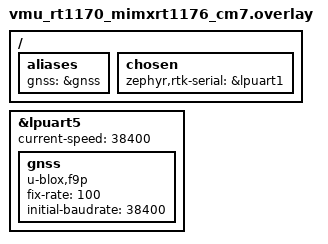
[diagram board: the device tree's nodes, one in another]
/*
 * Copyright 2024, 2026 NXP
 *
 * SPDX-License-Identifier: Apache-2.0
 */

/ {
	aliases {
		gnss = &gnss;
	};

	chosen {
		zephyr,rtk-serial = &lpuart1;
	};
};

&lpuart5 {
	status = "okay";
	current-speed = <38400>;

	gnss: gnss {
		status = "okay";
		compatible = "u-blox,f9p";
		fix-rate = <100>;
		initial-baudrate = <38400>;
	};
};
